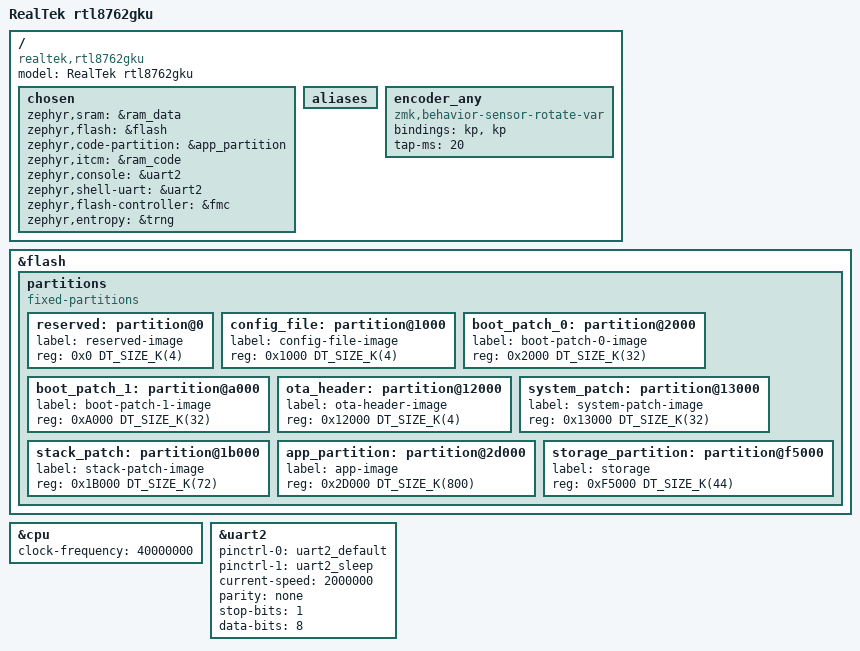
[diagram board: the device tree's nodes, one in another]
/dts-v1/;
#include <realtek/rtl87x2g.dtsi>
#include "rtl8762gku_kb-pinctrl.dtsi"
#include <behaviors.dtsi>
/ {
    model = "RealTek rtl8762gku ";
    compatible = "realtek,rtl8762gku";

    chosen {
        zephyr,sram = &ram_data;
        zephyr,flash = &flash;
        zephyr,code-partition = &app_partition;
        zephyr,itcm = &ram_code;
        zephyr,console = &uart2;
        zephyr,shell-uart = &uart2;
        zephyr,flash-controller = &fmc;
        zephyr,entropy = &trng;
    };

    /* These aliases are provided for compatibility with samples */
    aliases {
    };
    encoder_any: encoder_any {
        compatible = "zmk,behavior-sensor-rotate-var";
        #sensor-binding-cells = <2>;
        bindings = <&kp>, <&kp>;
        tap-ms =<20>;
    };
};

&flash {
    partitions {
        compatible = "fixed-partitions";
        #address-cells = <1>;
        #size-cells = <1>;
        reserved: partition@0 {
            label = "reserved-image";
            reg = <0x0 DT_SIZE_K(4)>;
        };
        config_file: partition@1000 {
            label = "config-file-image";
            reg = <0x1000 DT_SIZE_K(4)>;
        };
        boot_patch_0: partition@2000 {
            label = "boot-patch-0-image";
            reg = <0x2000 DT_SIZE_K(32)>;
        };
        boot_patch_1: partition@a000 {
            label = "boot-patch-1-image";
            reg = <0xA000 DT_SIZE_K(32)>;
        };
        ota_header: partition@12000 {
            label = "ota-header-image";
            reg = <0x12000 DT_SIZE_K(4)>;
        };
        system_patch: partition@13000 {
            label = "system-patch-image";
            reg = <0x13000 DT_SIZE_K(32)>;
        };
        stack_patch: partition@1b000 {
            label = "stack-patch-image";
            reg = <0x1B000 DT_SIZE_K(72)>;
        };
        app_partition: partition@2d000 {
            label = "app-image";
            reg = <0x2D000 DT_SIZE_K(800)>;
        };
        storage_partition: partition@f5000 {
            label = "storage";
            reg = <0xF5000 DT_SIZE_K(44)>;
        };
    };
};

&cpu {
    clock-frequency = <40000000>;
};

&uart2 {
    pinctrl-0 = <&uart2_default>;
    pinctrl-1 = <&uart2_sleep>;
    pinctrl-names = "default","sleep";
    status = "okay";
    current-speed = <2000000>;
    parity = "none";
    stop-bits = "1";
    data-bits = <8>;
};
